# RA register map
Vendor: Renesas; Series: All Chips; File version: x.xx
Registers are 32-bit, read-write, reset 0x0 unless marked. A register's access mark holds for its fields unless they carry their own. Offsets are from the block's base; [hi:lo] are bit positions; {n}, {i} and the like mark numbered series; 'fields as' and 'values as' point back to an identical list; <NAME> marks a mode.

## R_CTSU — Capacitive Touch Sensing Unit
Base 0x40081000
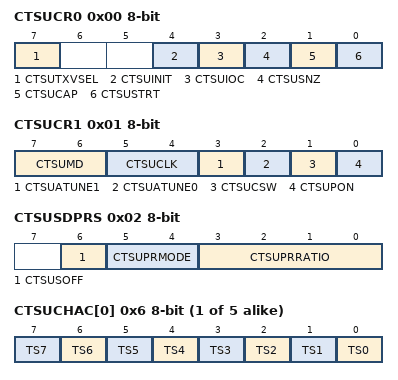
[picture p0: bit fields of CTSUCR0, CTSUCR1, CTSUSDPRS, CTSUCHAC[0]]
0x00 CTSUCR0 8-bit — CTSU Control Register 0
  [7] CTSUTXVSEL — CTSU Transmission power supply selection
    0=Select Vcc; 1=Select internal logic power supply
  [4] CTSUINIT — CTSU Control Block Initialization
    0=Writing a 0 has no effect, this bit is read as 0; 1=initializes the CTSU control block and registers
  [3] CTSUIOC — CTSU Transmit Pin Control
    0=Low-level output from transmit channel non-measurement pin; 1=High-level output from transmit channel non-measurement pin
  [2] CTSUSNZ — CTSU Wait State Power-Saving Enable
    0=Power-saving function during wait state is disabled; 1=Power-saving function during wait state is enabled
  [1] CTSUCAP — CTSU Measurement Operation Start Trigger Select
    0=Software trigger; 1=External trigger
  [0] CTSUSTRT — CTSU Measurement Operation Start
    0=Measurement operation stops; 1=Measurement operation starts
0x01 CTSUCR1 8-bit — CTSU Control Register 1
  [7:6] CTSUMD — CTSU Measurement Mode Select
    0=Self-capacitance single scan mode; 1=Self-capacitance multi-scan mode; 2=Mutual capacitance simple scan mode; 3=Mutual capacitance full scan mode
  [5:4] CTSUCLK — CTSU Operating Clock Select
    0=PCLK; 1=PCLK/2 (PCLK divided by 2); 2=PCLK/2 (PCLK divided by 4); 3=Setting prohibited
  [3] CTSUATUNE1 — CTSU Power Supply Capacity Adjustment
    0=Normal output; 1=High-current output
  [2] CTSUATUNE0 — CTSU Power Supply Operating Mode Setting
    0=Normal operating mode; 1=Low-voltage operating mode
  [1] CTSUCSW — CTSU LPF Capacitance Charging Control
    0=Turned off capacitance switch; 1=Turned on capacitance switch
  [0] CTSUPON — CTSU Power Supply Enable
    0=Powered off the CTSU; 1=Powered on the CTSU
0x02 CTSUSDPRS 8-bit — CTSU Synchronous Noise Reduction Setting Register
  [6] CTSUSOFF — CTSU High-Pass Noise Reduction Function Off Setting
    0=High-pass noise reduction function turned on; 1=High-pass noise reduction function turned off
  [5:4] CTSUPRMODE — CTSU Base Period and Pulse Count Setting
    0=510 pulses; 1=126 pulses; 2=62 pulses (recommended setting value); 3=Setting prohibited
  [3:0] CTSUPRRATIO — CTSU Measurement Time and Pulse Count AdjustmentRecommended setting: 3 (0011b)
0x03 CTSUSST 8-bit — CTSU Sensor Stabilization Wait Control Register
  [7:0] CTSUSST — CTSU Sensor Stabilization Wait ControlNOTE: The value of these bits should be fixed to 00010000b.
0x04 CTSUMCH0 8-bit reset 0x3F — CTSU Measurement Channel Register 0
  [5:0] CTSUMCH0 — CTSU Measurement Channel 0.Note1: Writing to these bits is only enabled in self-capacitance single-scan mode (CTSUCR1.CTSUMD[1:0] bits = 00b).Note2: If the value of CTSUMCH0 was set to b'111111 in mode other than self-capacitor single scan mode, the measurement is stopped.
    {v}=TS{v} (measured TS{v}) (v=0..35); 63=STOP (Conversion Stopped)
0x05 CTSUMCH1 8-bit reset 0x3F — CTSU Measurement Channel Register 1
  [5:0] CTSUMCH1 ro — CTSU Measurement Channel 1Note1: If the value of CTSUMCH1 was set to b'111111, the measurement is stopped.
    values as CTSUMCH0.CTSUMCH0
{0x6+i} CTSUCHAC[{i}] (i=0..4) 8-bit — CTSU Channel Enable Control Register
  [n] TS{n} (n=0..7) — CTSU Channel Enable Control
    0=Do not measure; 1=Measure
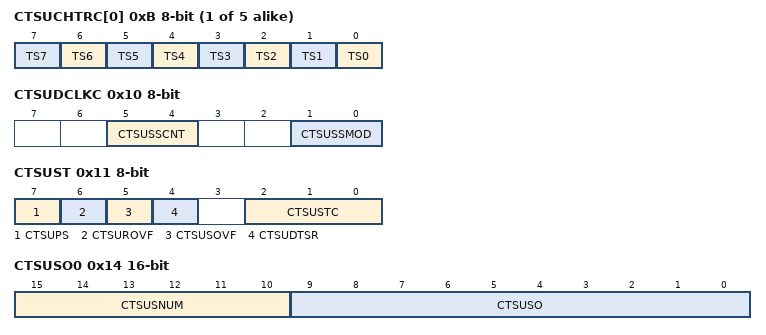
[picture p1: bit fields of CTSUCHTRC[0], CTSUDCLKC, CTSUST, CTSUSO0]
{0xB+i} CTSUCHTRC[{i}] (i=0..4) 8-bit — CTSU Channel Transmit/Receive Control Register
  [n] TS{n} (n=0..7) — CTSU Channel Transmit/Receive Control
    0=Reception; 1=Transmission
0x10 CTSUDCLKC 8-bit — CTSU High-Pass Noise Reduction Control Register
  [5:4] CTSUSSCNT — CTSU Diffusion Clock Mode ControlNOTE: This bit should be set to 11b.
  [1:0] CTSUSSMOD — CTSU Diffusion Clock Mode SelectNOTE: This bit should be set to 00b.
0x11 CTSUST 8-bit — CTSU Status Register
  [7] CTSUPS ro — CTSU Mutual Capacitance Status Flag
    0=First measurement; 1=Second measurement
  [6] CTSUROVF — CTSU Reference Counter Overflow Flag
    0=No overflow; 1=An overflow
  [5] CTSUSOVF — CTSU Sensor Counter Overflow Flag
    0=No overflow; 1=An overflow
  [4] CTSUDTSR ro — CTSU Data Transfer Status Flag
    0=Measurement result has been read; 1=Measurement result has not been read
  [2:0] CTSUSTC ro — CTSU Measurement Status Counter
    {v}=Status {v} (v=0..5)
0x12 CTSUSSC 16-bit — CTSU High-Pass Noise Reduction Spectrum Diffusion Control Register
  [11:8] CTSUSSDIV — CTSU Spectrum Diffusion Frequency Division Setting
    0=4.00 <= fb; 1=2.00 <= fb < 4.00; 2=1.33 <= fb < 2.00; 3=1.00 <= fb < 1.33; 4=0.80 <= fb < 1.00; 5=0.67 <= fb < 0.80; 6=0.57 <= fb < 0.67; 7=0.50 <= fb < 0.57; 8=0.44 <= fb < 0.50; 9=0.40 <= fb < 0.44; 10=0.36 <= fb < 0.40; 11=0.33 <= fb < 0.36; 12=0.31 <= fb < 0.33; 13=0.29 <= fb < 0.31; 14=0.27 <= fb < 0.29; 15=fb < 0.27
0x14 CTSUSO0 16-bit — CTSU Sensor Offset Register 0
  [15:10] CTSUSNUM — CTSU Measurement Count Setting
  [9:0] CTSUSO — CTSU Sensor Offset AdjustmentCurrent offset amount is CTSUSO ( 0 to 1023 )
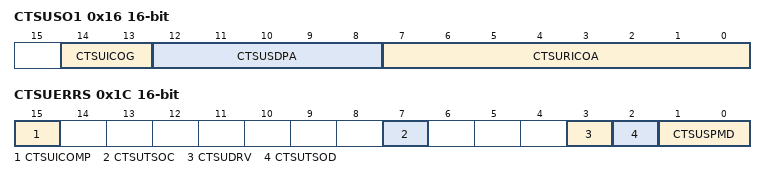
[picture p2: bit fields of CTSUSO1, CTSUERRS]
0x16 CTSUSO1 16-bit — CTSU Sensor Offset Register 1
  [14:13] CTSUICOG — CTSU ICO Gain Adjustment
    0=100 percent gain; 1=66 percent gain; 2=50 percent gain; 3=40 percent gain
  [12:8] CTSUSDPA — CTSU Base Clock SettingOperating clock divided by ( CTSUSDPA + 1 ) x 2
  [7:0] CTSURICOA — CTSU Reference ICO Current AdjustmentCurrent offset amount is CTSUSO ( 0 to 255 )
0x18 CTSUSC 16-bit ro — CTSU Sensor Counter
  [15:0] CTSUSC — CTSU Sensor CounterThese bits indicate the measurement result of the CTSU. These bits indicate FFFFh when an overflow occurs.
0x1A CTSURC 16-bit ro — CTSU Reference Counter
  [15:0] CTSURC — CTSU Reference CounterThese bits indicate the measurement result of the reference ICO.These bits indicate FFFFh when an overflow occurs.
0x1C CTSUERRS 16-bit ro — CTSU Error Status Register
  [15] CTSUICOMP — TSCAP Voltage Error Monitor
    0=Normal TSCAP voltage; 1=Abnormal TSCAP voltage
  [7] CTSUTSOC rw — Calibration Setting 2
    0=Capacitance measurement mode; 1=Calibration setting 2
  [3] CTSUDRV rw — Calibration Setting 1
    0=Capacitance measurement mode; 1=Calibration setting 1
  [2] CTSUTSOD rw — TS Pin Fixed Output
    0=Capacitance measurement mode; 1=TS pins are forced to be high or low
  [1:0] CTSUSPMD rw — Calibration Mode
    0=Capacitance measurement mode; 2=Calibration mode; other=Others (Seting prohibited)
0x20 CTSUTRMR 8-bit reset not defined — CTSU Reference Current Calibration Register
